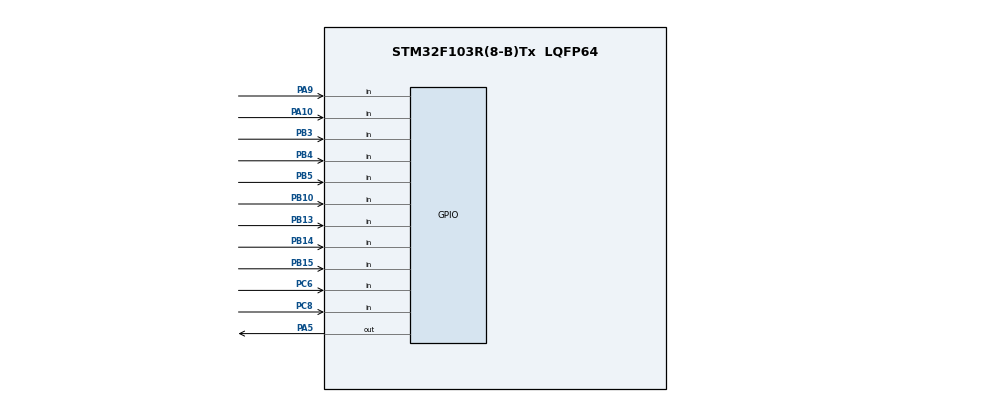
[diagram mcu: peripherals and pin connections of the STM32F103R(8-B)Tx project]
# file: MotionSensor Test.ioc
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Mcu.Family=STM32F1
PC8.Signal=GPIO_Input
PC6.Signal=GPIO_Input
PB13.Signal=GPIO_Input
PB15.Signal=GPIO_Input
ProjectManager.StackSize=0x400
PA13.Signal=SYS_JTMS-SWDIO
ProjectManager.TargetToolchain=STM32CubeIDE
PA9.Signal=GPIO_Input
PB10.Signal=GPIO_Input
PB14.Signal=GPIO_Input
PA5.Signal=GPIO_Output
board=custom
RCC.APB2Freq_Value=8000000
PA14.Mode=Serial_Wire
PA13.Mode=Serial_Wire
Mcu.Name=STM32F103R(8-B)Tx
PB3.Signal=GPIO_Input
Mcu.Package=LQFP64
PB5.Signal=GPIO_Input
PA10.Signal=GPIO_Input
PA14.Signal=SYS_JTCK-SWCLK
ProjectManager.HeapSize=0x200
NVIC.PriorityGroup=NVIC_PRIORITYGROUP_4
RCC.APB1Freq_Value=8000000
PB4.Signal=GPIO_Input

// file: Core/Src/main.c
/* USER CODE BEGIN Header */
/**
 ******************************************************************************
 * @file           : main.c
 * @brief          : Main program body
 ******************************************************************************
 * @attention
 *
 * <h2><center>&copy; Copyright (c) 2021 STMicroelectronics.
 * All rights reserved.</center></h2>
 *
 * This software component is licensed by ST under BSD 3-Clause license,
 * the "License"; You may not use this file except in compliance with the
 * License. You may obtain a copy of the License at:
 *                        opensource.org/licenses/BSD-3-Clause
 *
 ******************************************************************************
 */
/* USER CODE END Header */
#include "main.h"

void SystemClock_Config(void);
static void MX_GPIO_Init(void);

int main(void)
{

  /* MCU Configuration--------------------------------------------------------*/

  /* Reset of all peripherals, Initializes the Flash interface and the Systick. */
  HAL_Init();

  /* Configure the system clock */
  SystemClock_Config();

  /* Initialize all configured peripherals */
  MX_GPIO_Init();

  /* Infinite loop */
  /* USER CODE BEGIN WHILE */
	while (1) {

		if (HAL_GPIO_ReadPin(GPIOB, GPIO_PIN_15)) {
			HAL_GPIO_WritePin(GPIOA, GPIO_PIN_5, GPIO_PIN_SET);
			HAL_Delay(1000);
		} else {
			HAL_GPIO_WritePin(GPIOA, GPIO_PIN_5, GPIO_PIN_RESET);
			HAL_Delay(1000);
		}
    /* USER CODE END WHILE */

	}
}

void SystemClock_Config(void)
{
  RCC_OscInitTypeDef RCC_OscInitStruct = {0};
  RCC_ClkInitTypeDef RCC_ClkInitStruct = {0};

  /** Initializes the RCC Oscillators according to the specified parameters
  * in the RCC_OscInitTypeDef structure.
  */
  RCC_OscInitStruct.OscillatorType = RCC_OSCILLATORTYPE_HSI;
  RCC_OscInitStruct.HSIState = RCC_HSI_ON;
  RCC_OscInitStruct.HSICalibrationValue = RCC_HSICALIBRATION_DEFAULT;
  RCC_OscInitStruct.PLL.PLLState = RCC_PLL_NONE;
  if (HAL_RCC_OscConfig(&RCC_OscInitStruct) != HAL_OK)
  {
    Error_Handler();
  }
  /** Initializes the CPU, AHB and APB buses clocks
  */
  RCC_ClkInitStruct.ClockType = RCC_CLOCKTYPE_HCLK|RCC_CLOCKTYPE_SYSCLK
                              |RCC_CLOCKTYPE_PCLK1|RCC_CLOCKTYPE_PCLK2;
  RCC_ClkInitStruct.SYSCLKSource = RCC_SYSCLKSOURCE_HSI;
  RCC_ClkInitStruct.AHBCLKDivider = RCC_SYSCLK_DIV1;
  RCC_ClkInitStruct.APB1CLKDivider = RCC_HCLK_DIV1;
  RCC_ClkInitStruct.APB2CLKDivider = RCC_HCLK_DIV1;

  if (HAL_RCC_ClockConfig(&RCC_ClkInitStruct, FLASH_LATENCY_0) != HAL_OK)
  {
    Error_Handler();
  }
}

static void MX_GPIO_Init(void)
{
  GPIO_InitTypeDef GPIO_InitStruct = {0};

  /* GPIO Ports Clock Enable */
  __HAL_RCC_GPIOA_CLK_ENABLE();
  __HAL_RCC_GPIOB_CLK_ENABLE();
  __HAL_RCC_GPIOC_CLK_ENABLE();

  /*Configure GPIO pin Output Level */
  HAL_GPIO_WritePin(GPIOA, GPIO_PIN_5, GPIO_PIN_RESET);

  /*Configure GPIO pin : PA5 */
  GPIO_InitStruct.Pin = GPIO_PIN_5;
  GPIO_InitStruct.Mode = GPIO_MODE_OUTPUT_PP;
  GPIO_InitStruct.Pull = GPIO_NOPULL;
  GPIO_InitStruct.Speed = GPIO_SPEED_FREQ_LOW;
  HAL_GPIO_Init(GPIOA, &GPIO_InitStruct);

  /*Configure GPIO pins : PB10 PB13 PB14 PB15
                           PB3 PB4 PB5 */
  GPIO_InitStruct.Pin = GPIO_PIN_10|GPIO_PIN_13|GPIO_PIN_14|GPIO_PIN_15
                          |GPIO_PIN_3|GPIO_PIN_4|GPIO_PIN_5;
  GPIO_InitStruct.Mode = GPIO_MODE_INPUT;
  GPIO_InitStruct.Pull = GPIO_NOPULL;
  HAL_GPIO_Init(GPIOB, &GPIO_InitStruct);

  /*Configure GPIO pins : PC6 PC8 */
  GPIO_InitStruct.Pin = GPIO_PIN_6|GPIO_PIN_8;
  GPIO_InitStruct.Mode = GPIO_MODE_INPUT;
  GPIO_InitStruct.Pull = GPIO_NOPULL;
  HAL_GPIO_Init(GPIOC, &GPIO_InitStruct);

  /*Configure GPIO pins : PA9 PA10 */
  GPIO_InitStruct.Pin = GPIO_PIN_9|GPIO_PIN_10;
  GPIO_InitStruct.Mode = GPIO_MODE_INPUT;
  GPIO_InitStruct.Pull = GPIO_NOPULL;
  HAL_GPIO_Init(GPIOA, &GPIO_InitStruct);

}

void Error_Handler(void)
{
	__disable_irq();
	while (1) {
	}
}

/************************ (C) COPYRIGHT STMicroelectronics *****END OF FILE****/
